VERSION ""

NS_ :

BS_:

BU_: IRTS_RR TLM ACQUISINATOR ACQUISINATOR IRTS_RR TLM IRTS_RR TLM ACQUISINATOR IRTS_RR TLM TLM ACQUISINATOR ACQUISINATOR TLM ACQUISINATOR TLM TLM ACQUISINATOR ACQUISINATOR ECU TLM TLM DITOCAN ACQUISINATOR TLM TLM TLM TLM TLM ACQUISINATOR ACQUISINATOR ACQUISINATOR TLM TLM TLM ACQUISINATOR ACQUISINATOR ACQUISINATOR TLM TLM TLM ACQUISINATOR ACQUISINATOR TLM TLM TLM ECU ACQUISINATOR ECU TLM TLM ACQUISINATOR ECU TLM TLM ACQUISINATOR ACQUISINATOR TLM TLM TLM ACQUISINATOR ACQUISINATOR TLM ACQUISINATOR ACQUISINATOR ACQUISINATOR ACQUISINATOR TLM TLM ACQUISINATOR ACQUISINATOR ACQUISINATOR ACQUISINATOR ACQUISINATOR ACQUISINATOR TLM TLM ACQUISINATOR TLM TLM ACQUISINATOR TLM TLM TLM TLM ACQUISINATOR ACQUISINATOR TLM TLM TLM ANY TLM ACQUISINATOR ANY TLM TLM ACQUISINATOR ANY ACQUISINATOR ANY ACQUISINATOR TLM TLM ACQUISINATOR TLM ACQUISINATOR ACQUISINATOR ACQUISINATOR ACQUISINATOR TLM TLM ACQUISINATOR TLM TLM ACQUISINATOR ACQUISINATOR ACQUISINATOR TLM TLM ACQUISINATOR ACQUISINATOR TLM ACQUISINATOR TLM TLM TLM ACQUISINATOR ACQUISINATOR TLM ACQUISINATOR TLM TLM ACQUISINATOR TLM TLM TLM ACQUISINATOR TLM TLM ACQUISINATOR ACQUISINATOR TLM ACQUISINATOR ACQUISINATOR ACQUISINATOR TLM ACQUISINATOR TLM ACQUISINATOR TLM ACQUISINATOR ACQUISINATOR TLM ACQUISINATOR TLM TLM ACQUISINATOR TLM ACQUISINATOR ACQUISINATOR IMU IMU IRTS_FL ACQUISINATOR IRTS_FL IRTS_FL IRTS_FL IRTS_FR TLM IRTS_FR ACQUISINATOR IRTS_FR TLM ACQUISINATOR ACQUISINATOR TLM TLM TLM ACQUISINATOR ACQUISINATOR TLM IRTS_FR ACQUISINATOR IRTS_RL ACQUISINATOR IRTS_RL IRTS_RL IRTS_RL

BO_ 0 ACQUISINATOR_JMP_TO_BLT: 1 Vector__XXX
 SG_ acquisinatore_id : 0|8@1+ (1,0) [0|255] "" Vector__XXX

BO_ 1 ACQUISINATOR_FLASH_0_TX: 0 Vector__XXX

BO_ 2 ACQUISINATOR_FLASH_0_RX: 0 Vector__XXX

BO_ 3 ACQUISINATOR_FLASH_1_TX: 0 Vector__XXX

BO_ 4 ACQUISINATOR_FLASH_1_RX: 0 Vector__XXX

BO_ 5 ACQUISINATOR_FLASH_2_TX: 0 Vector__XXX

BO_ 6 ACQUISINATOR_FLASH_2_RX: 0 Vector__XXX

BO_ 7 ACQUISINATOR_FLASH_3_TX: 0 Vector__XXX

BO_ 8 ACQUISINATOR_FLASH_3_RX: 0 Vector__XXX

BO_ 9 ACQUISINATOR_FLASH_4_TX: 0 Vector__XXX

BO_ 10 ACQUISINATOR_FLASH_4_RX: 0 Vector__XXX

BO_ 11 ACQUISINATOR_FLASH_5_TX: 0 Vector__XXX

BO_ 12 ACQUISINATOR_FLASH_5_RX: 0 Vector__XXX

BO_ 13 ACQUISINATOR_FLASH_6_TX: 0 Vector__XXX

BO_ 14 ACQUISINATOR_FLASH_6_RX: 0 Vector__XXX

BO_ 15 ACQUISINATOR_FLASH_7_TX: 0 Vector__XXX

BO_ 16 ACQUISINATOR_FLASH_7_RX: 0 Vector__XXX

BO_ 17 ACQUISINATOR_FLASH_8_TX: 0 Vector__XXX

BO_ 18 ACQUISINATOR_FLASH_8_RX: 0 Vector__XXX

BO_ 19 ACQUISINATOR_FLASH_9_TX: 0 Vector__XXX

BO_ 20 ACQUISINATOR_FLASH_9_RX: 0 Vector__XXX

BO_ 21 ACQUISINATOR_FLASH_10_TX: 0 Vector__XXX

BO_ 22 ACQUISINATOR_FLASH_10_RX: 0 Vector__XXX

BO_ 23 ACQUISINATOR_FLASH_11_TX: 0 Vector__XXX

BO_ 24 ACQUISINATOR_FLASH_11_RX: 0 Vector__XXX

BO_ 25 ACQUISINATOR_FLASH_12_TX: 0 Vector__XXX

BO_ 26 ACQUISINATOR_FLASH_12_RX: 0 Vector__XXX

BO_ 27 ACQUISINATOR_FLASH_13_TX: 0 Vector__XXX

BO_ 28 ACQUISINATOR_FLASH_13_RX: 0 Vector__XXX

BO_ 29 ACQUISINATOR_FLASH_14_TX: 0 Vector__XXX

BO_ 30 ACQUISINATOR_FLASH_14_RX: 0 Vector__XXX

BO_ 31 ACQUISINATOR_FLASH_15_TX: 0 Vector__XXX

BO_ 32 ACQUISINATOR_FLASH_15_RX: 0 Vector__XXX

BO_ 33 ACQUISINATOR_FLASH_16_TX: 0 Vector__XXX

BO_ 34 ACQUISINATOR_FLASH_16_RX: 0 Vector__XXX

BO_ 35 ACQUISINATOR_FLASH_17_TX: 0 Vector__XXX

BO_ 36 ACQUISINATOR_FLASH_17_RX: 0 Vector__XXX

BO_ 37 ACQUISINATOR_FLASH_18_TX: 0 Vector__XXX

BO_ 38 ACQUISINATOR_FLASH_18_RX: 0 Vector__XXX

BO_ 39 ACQUISINATOR_FLASH_19_TX: 0 Vector__XXX

BO_ 40 ACQUISINATOR_FLASH_19_RX: 0 Vector__XXX

BO_ 41 ACQUISINATOR_FLASH_20_TX: 0 Vector__XXX

BO_ 42 ACQUISINATOR_FLASH_20_RX: 0 Vector__XXX

BO_ 43 ACQUISINATOR_FLASH_21_TX: 0 Vector__XXX

BO_ 44 ACQUISINATOR_FLASH_21_RX: 0 Vector__XXX

BO_ 45 ACQUISINATOR_FLASH_22_TX: 0 Vector__XXX

BO_ 46 ACQUISINATOR_FLASH_22_RX: 0 Vector__XXX

BO_ 47 ACQUISINATOR_FLASH_23_TX: 0 Vector__XXX

BO_ 48 ACQUISINATOR_FLASH_23_RX: 0 Vector__XXX

BO_ 49 ACQUISINATOR_FLASH_24_TX: 0 Vector__XXX

BO_ 50 ACQUISINATOR_FLASH_24_RX: 0 Vector__XXX

BO_ 51 ACQUISINATOR_FLASH_25_TX: 0 Vector__XXX

BO_ 52 ACQUISINATOR_FLASH_25_RX: 0 Vector__XXX

BO_ 53 ACQUISINATOR_FLASH_26_TX: 0 Vector__XXX

BO_ 54 ACQUISINATOR_FLASH_26_RX: 0 Vector__XXX

BO_ 55 ACQUISINATOR_FLASH_27_TX: 0 Vector__XXX

BO_ 56 ACQUISINATOR_FLASH_27_RX: 0 Vector__XXX

BO_ 57 ACQUISINATOR_FLASH_28_TX: 0 Vector__XXX

BO_ 58 ACQUISINATOR_FLASH_28_RX: 0 Vector__XXX

BO_ 59 ACQUISINATOR_FLASH_29_TX: 0 Vector__XXX

BO_ 60 ACQUISINATOR_FLASH_29_RX: 0 Vector__XXX

BO_ 61 ACQUISINATOR_FLASH_30_TX: 0 Vector__XXX

BO_ 62 ACQUISINATOR_FLASH_30_RX: 0 Vector__XXX

BO_ 63 ACQUISINATOR_FLASH_31_TX: 0 Vector__XXX

BO_ 64 ACQUISINATOR_FLASH_31_RX: 0 Vector__XXX

BO_ 700 ACQUISINATOR_VERSION: 5 Vector__XXX
 SG_ canlib_build_time : 8|32@1+ (1,0) [0|4294967295] "" Vector__XXX
 SG_ acquisinator_id : 0|8@1+ (1,0) [0|255] "" Vector__XXX

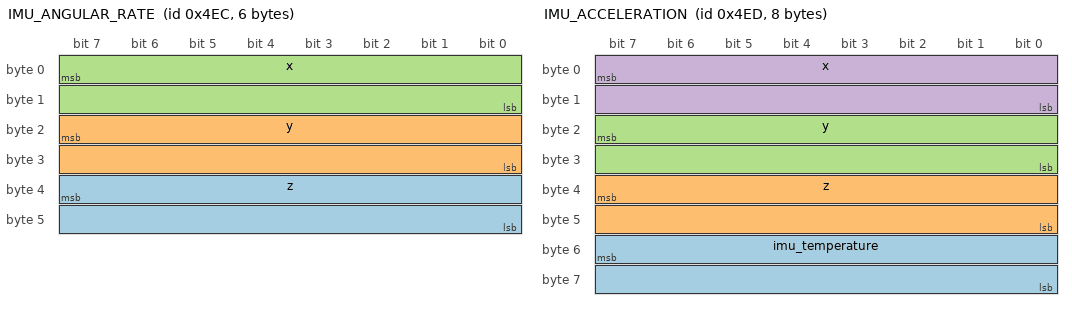
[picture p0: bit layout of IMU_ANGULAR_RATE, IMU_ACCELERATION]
BO_ 1260 IMU_ANGULAR_RATE: 6 Vector__XXX
 SG_ z : 39|16@0- (0.01,0) [0|245] "" Vector__XXX
 SG_ y : 23|16@0- (0.01,0) [0|245] "" Vector__XXX
 SG_ x : 7|16@0- (0.01,0) [0|245] "" Vector__XXX

BO_ 1261 IMU_ACCELERATION: 8 Vector__XXX
 SG_ imu_temperature : 55|16@0- (1,-32768) [-32768|32767] "" Vector__XXX
 SG_ z : 39|16@0- (0.01,0) [0|8] "" Vector__XXX
 SG_ y : 23|16@0- (0.01,0) [0|8] "" Vector__XXX
 SG_ x : 7|16@0- (0.01,0) [0|8] "" Vector__XXX

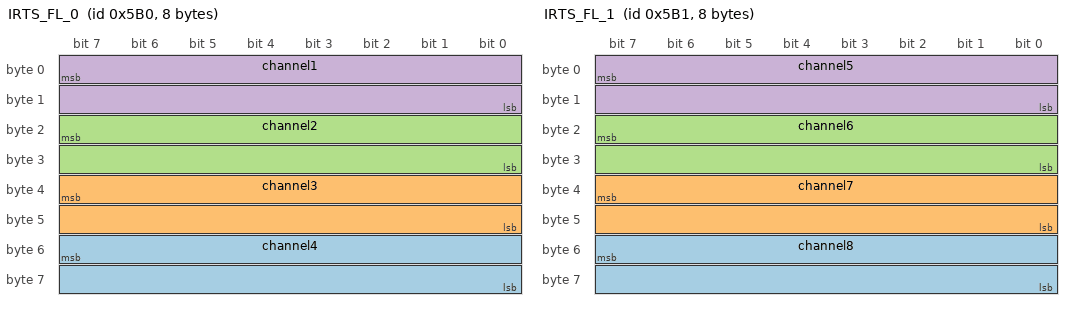
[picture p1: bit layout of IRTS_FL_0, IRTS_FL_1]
BO_ 1456 IRTS_FL_0: 8 Vector__XXX
 SG_ channel4 : 55|16@0+ (0.1,-100) [-100|0] "" Vector__XXX
 SG_ channel3 : 39|16@0+ (0.1,-100) [-100|0] "" Vector__XXX
 SG_ channel2 : 23|16@0+ (0.1,-100) [-100|0] "" Vector__XXX
 SG_ channel1 : 7|16@0+ (0.1,-100) [-100|0] "" Vector__XXX

BO_ 1457 IRTS_FL_1: 8 Vector__XXX
 SG_ channel8 : 55|16@0+ (0.1,-100) [-100|0] "" Vector__XXX
 SG_ channel7 : 39|16@0+ (0.1,-100) [-100|0] "" Vector__XXX
 SG_ channel6 : 23|16@0+ (0.1,-100) [-100|0] "" Vector__XXX
 SG_ channel5 : 7|16@0+ (0.1,-100) [-100|0] "" Vector__XXX

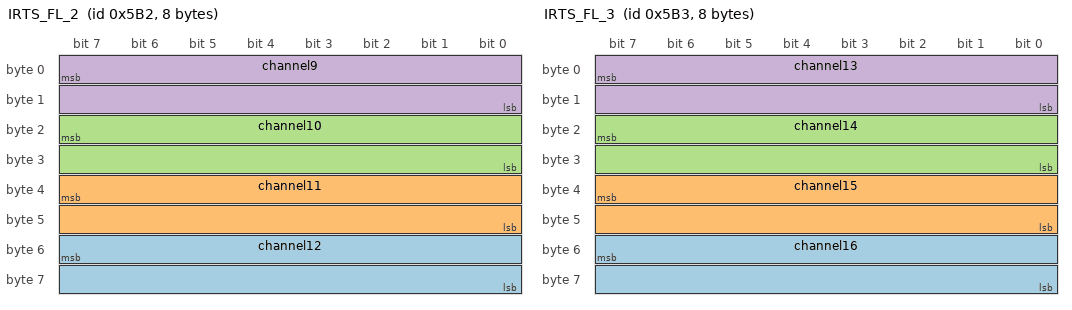
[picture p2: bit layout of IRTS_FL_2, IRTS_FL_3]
BO_ 1458 IRTS_FL_2: 8 Vector__XXX
 SG_ channel12 : 55|16@0+ (0.1,-100) [-100|0] "" Vector__XXX
 SG_ channel11 : 39|16@0+ (0.1,-100) [-100|0] "" Vector__XXX
 SG_ channel10 : 23|16@0+ (0.1,-100) [-100|0] "" Vector__XXX
 SG_ channel9 : 7|16@0+ (0.1,-100) [-100|0] "" Vector__XXX

BO_ 1459 IRTS_FL_3: 8 Vector__XXX
 SG_ channel16 : 55|16@0+ (0.1,-100) [-100|0] "" Vector__XXX
 SG_ channel15 : 39|16@0+ (0.1,-100) [-100|0] "" Vector__XXX
 SG_ channel14 : 23|16@0+ (0.1,-100) [-100|0] "" Vector__XXX
 SG_ channel13 : 7|16@0+ (0.1,-100) [-100|0] "" Vector__XXX

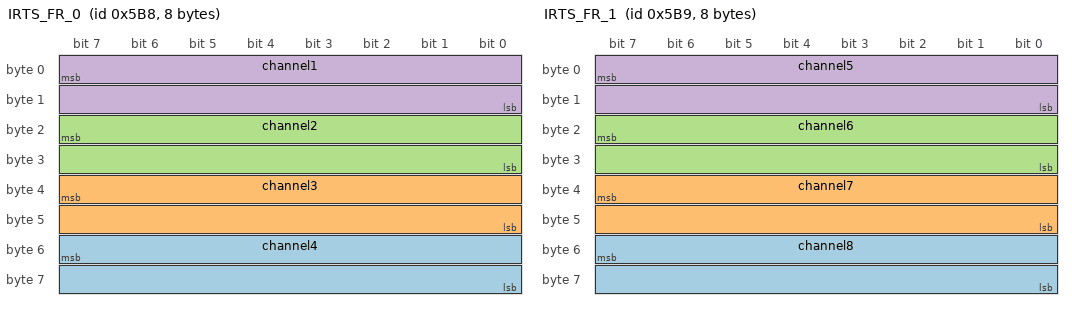
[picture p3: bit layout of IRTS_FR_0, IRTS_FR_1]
BO_ 1464 IRTS_FR_0: 8 Vector__XXX
 SG_ channel4 : 55|16@0+ (0.1,-100) [-100|0] "" Vector__XXX
 SG_ channel3 : 39|16@0+ (0.1,-100) [-100|0] "" Vector__XXX
 SG_ channel2 : 23|16@0+ (0.1,-100) [-100|0] "" Vector__XXX
 SG_ channel1 : 7|16@0+ (0.1,-100) [-100|0] "" Vector__XXX

BO_ 1465 IRTS_FR_1: 8 Vector__XXX
 SG_ channel8 : 55|16@0+ (0.1,-100) [-100|0] "" Vector__XXX
 SG_ channel7 : 39|16@0+ (0.1,-100) [-100|0] "" Vector__XXX
 SG_ channel6 : 23|16@0+ (0.1,-100) [-100|0] "" Vector__XXX
 SG_ channel5 : 7|16@0+ (0.1,-100) [-100|0] "" Vector__XXX

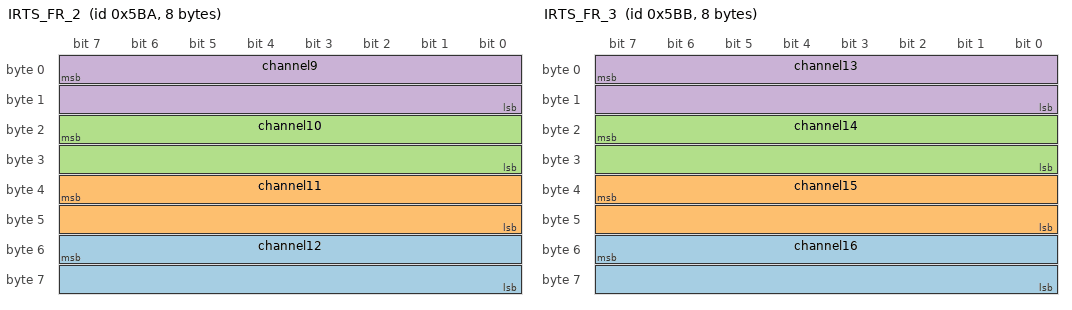
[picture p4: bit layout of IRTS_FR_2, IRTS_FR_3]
BO_ 1466 IRTS_FR_2: 8 Vector__XXX
 SG_ channel12 : 55|16@0+ (0.1,-100) [-100|0] "" Vector__XXX
 SG_ channel11 : 39|16@0+ (0.1,-100) [-100|0] "" Vector__XXX
 SG_ channel10 : 23|16@0+ (0.1,-100) [-100|0] "" Vector__XXX
 SG_ channel9 : 7|16@0+ (0.1,-100) [-100|0] "" Vector__XXX

BO_ 1467 IRTS_FR_3: 8 Vector__XXX
 SG_ channel16 : 55|16@0+ (0.1,-100) [-100|0] "" Vector__XXX
 SG_ channel15 : 39|16@0+ (0.1,-100) [-100|0] "" Vector__XXX
 SG_ channel14 : 23|16@0+ (0.1,-100) [-100|0] "" Vector__XXX
 SG_ channel13 : 7|16@0+ (0.1,-100) [-100|0] "" Vector__XXX

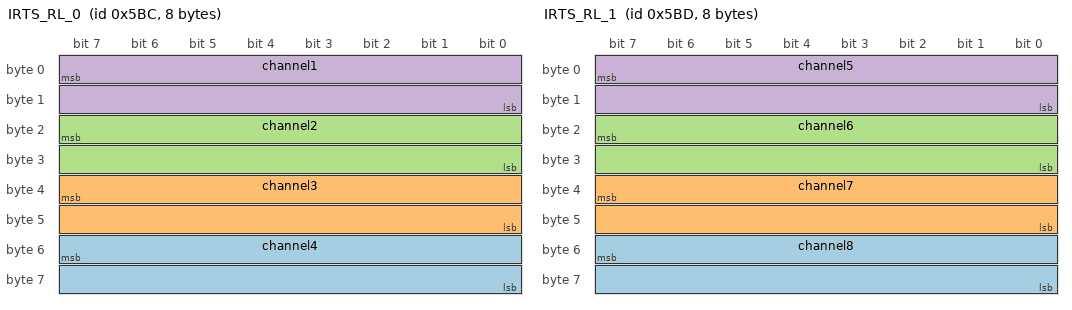
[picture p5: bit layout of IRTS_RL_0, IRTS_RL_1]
BO_ 1468 IRTS_RL_0: 8 Vector__XXX
 SG_ channel4 : 55|16@0+ (0.1,-100) [-100|0] "" Vector__XXX
 SG_ channel3 : 39|16@0+ (0.1,-100) [-100|0] "" Vector__XXX
 SG_ channel2 : 23|16@0+ (0.1,-100) [-100|0] "" Vector__XXX
 SG_ channel1 : 7|16@0+ (0.1,-100) [-100|0] "" Vector__XXX

BO_ 1469 IRTS_RL_1: 8 Vector__XXX
 SG_ channel8 : 55|16@0+ (0.1,-100) [-100|0] "" Vector__XXX
 SG_ channel7 : 39|16@0+ (0.1,-100) [-100|0] "" Vector__XXX
 SG_ channel6 : 23|16@0+ (0.1,-100) [-100|0] "" Vector__XXX
 SG_ channel5 : 7|16@0+ (0.1,-100) [-100|0] "" Vector__XXX

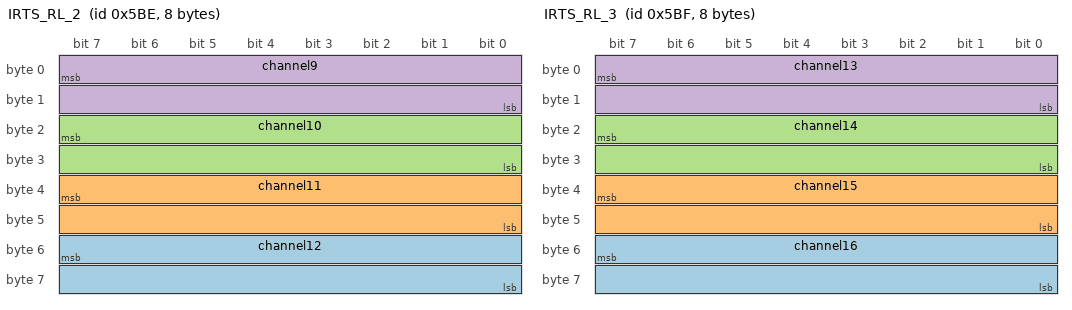
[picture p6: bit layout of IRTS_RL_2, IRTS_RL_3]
BO_ 1470 IRTS_RL_2: 8 Vector__XXX
 SG_ channel12 : 55|16@0+ (0.1,-100) [-100|0] "" Vector__XXX
 SG_ channel11 : 39|16@0+ (0.1,-100) [-100|0] "" Vector__XXX
 SG_ channel10 : 23|16@0+ (0.1,-100) [-100|0] "" Vector__XXX
 SG_ channel9 : 7|16@0+ (0.1,-100) [-100|0] "" Vector__XXX

BO_ 1471 IRTS_RL_3: 8 Vector__XXX
 SG_ channel16 : 55|16@0+ (0.1,-100) [-100|0] "" Vector__XXX
 SG_ channel15 : 39|16@0+ (0.1,-100) [-100|0] "" Vector__XXX
 SG_ channel14 : 23|16@0+ (0.1,-100) [-100|0] "" Vector__XXX
 SG_ channel13 : 7|16@0+ (0.1,-100) [-100|0] "" Vector__XXX

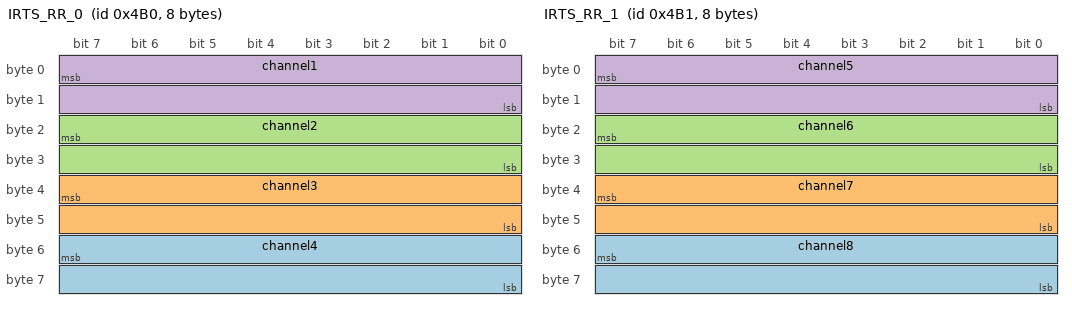
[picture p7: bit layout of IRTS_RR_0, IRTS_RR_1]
BO_ 1200 IRTS_RR_0: 8 Vector__XXX
 SG_ channel4 : 55|16@0+ (0.1,-100) [-100|0] "" Vector__XXX
 SG_ channel3 : 39|16@0+ (0.1,-100) [-100|0] "" Vector__XXX
 SG_ channel2 : 23|16@0+ (0.1,-100) [-100|0] "" Vector__XXX
 SG_ channel1 : 7|16@0+ (0.1,-100) [-100|0] "" Vector__XXX

BO_ 1201 IRTS_RR_1: 8 Vector__XXX
 SG_ channel8 : 55|16@0+ (0.1,-100) [-100|0] "" Vector__XXX
 SG_ channel7 : 39|16@0+ (0.1,-100) [-100|0] "" Vector__XXX
 SG_ channel6 : 23|16@0+ (0.1,-100) [-100|0] "" Vector__XXX
 SG_ channel5 : 7|16@0+ (0.1,-100) [-100|0] "" Vector__XXX

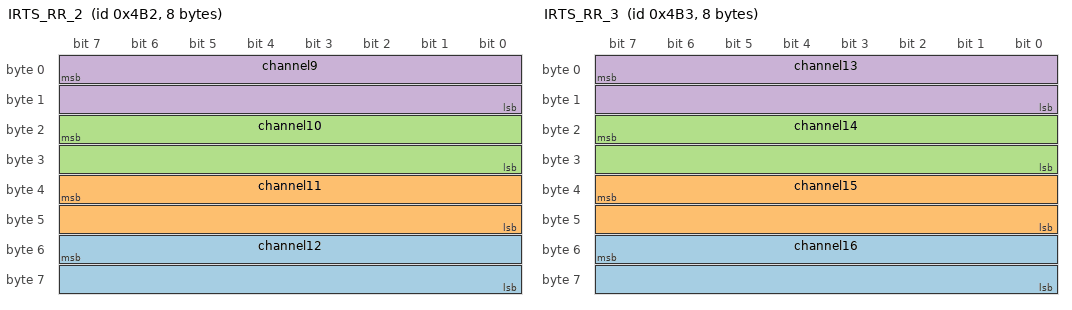
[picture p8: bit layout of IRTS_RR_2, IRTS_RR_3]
BO_ 1202 IRTS_RR_2: 8 Vector__XXX
 SG_ channel12 : 55|16@0+ (0.1,-100) [-100|0] "" Vector__XXX
 SG_ channel11 : 39|16@0+ (0.1,-100) [-100|0] "" Vector__XXX
 SG_ channel10 : 23|16@0+ (0.1,-100) [-100|0] "" Vector__XXX
 SG_ channel9 : 7|16@0+ (0.1,-100) [-100|0] "" Vector__XXX

BO_ 1203 IRTS_RR_3: 8 Vector__XXX
 SG_ channel16 : 55|16@0+ (0.1,-100) [-100|0] "" Vector__XXX
 SG_ channel15 : 39|16@0+ (0.1,-100) [-100|0] "" Vector__XXX
 SG_ channel14 : 23|16@0+ (0.1,-100) [-100|0] "" Vector__XXX
 SG_ channel13 : 7|16@0+ (0.1,-100) [-100|0] "" Vector__XXX

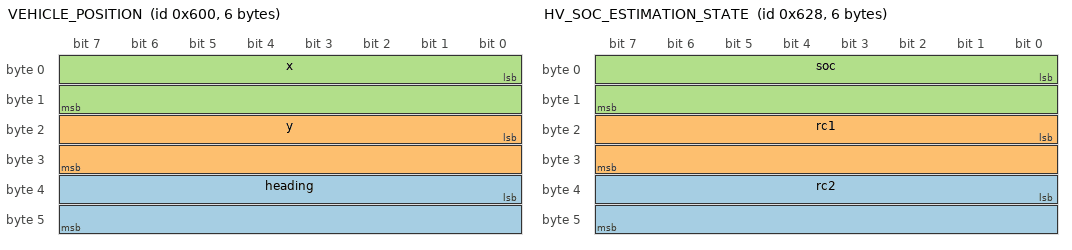
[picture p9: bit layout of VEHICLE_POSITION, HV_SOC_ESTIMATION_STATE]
BO_ 1536 VEHICLE_POSITION: 6 Vector__XXX
 SG_ heading : 32|16@1+ (9.587518120088503e-05,-3.14159) [-3.14159|3.14159] "" Vector__XXX
 SG_ y : 16|16@1+ (0.030518043793392843,-1000) [-1000|1000] "" Vector__XXX
 SG_ x : 0|16@1+ (0.030518043793392843,-1000) [-1000|1000] "" Vector__XXX

BO_ 1544 VEHICLE_SPEED: 4 Vector__XXX
 SG_ v : 16|16@1+ (0.0006103608758678569,-20) [-20|20] "" Vector__XXX
 SG_ u : 0|16@1+ (0.0006103608758678569,0) [0|40] "" Vector__XXX

BO_ 1552 VEHICLE_CURVILINEAR_COORDINATES: 6 Vector__XXX
 SG_ n : 32|16@1+ (0.00030518043793392844,-10) [-10|10] "" Vector__XXX
 SG_ s : 0|32@1+ (1.1641532185403987e-06,0) [0|5000] "" Vector__XXX

BO_ 1560 FRONT_ANGULAR_VELOCITY: 4 Vector__XXX
 SG_ fr : 16|16@1+ (0.006103608758678569,-200) [-200|200] "" Vector__XXX
 SG_ fl : 0|16@1+ (0.006103608758678569,-200) [-200|200] "" Vector__XXX

BO_ 1568 REAR_ANGULAR_VELOCITY: 4 Vector__XXX
 SG_ rr : 16|16@1+ (0.006103608758678569,-200) [-200|200] "" Vector__XXX
 SG_ rl : 0|16@1+ (0.006103608758678569,-200) [-200|200] "" Vector__XXX

BO_ 1576 HV_SOC_ESTIMATION_STATE: 6 Vector__XXX
 SG_ rc2 : 32|16@1+ (6.86655985351339e-05,0) [0|4.5] "" Vector__XXX
 SG_ rc1 : 16|16@1+ (6.86655985351339e-05,0) [0|4.5] "" Vector__XXX
 SG_ soc : 0|16@1+ (1.5259021896696422e-05,0) [0|1] "" Vector__XXX

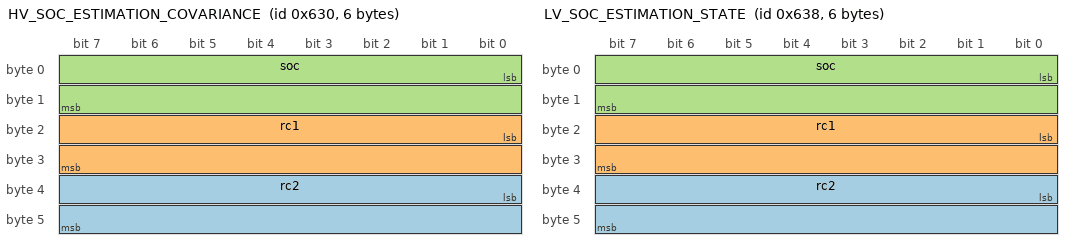
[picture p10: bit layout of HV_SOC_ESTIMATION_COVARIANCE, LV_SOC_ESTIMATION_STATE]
BO_ 1584 HV_SOC_ESTIMATION_COVARIANCE: 6 Vector__XXX
 SG_ rc2 : 32|16@1+ (0.0015259021896696422,0) [0|100] "" Vector__XXX
 SG_ rc1 : 16|16@1+ (0.0015259021896696422,0) [0|100] "" Vector__XXX
 SG_ soc : 0|16@1+ (0.00015259021896696422,0) [0|10] "" Vector__XXX

BO_ 1592 LV_SOC_ESTIMATION_STATE: 6 Vector__XXX
 SG_ rc2 : 32|16@1+ (6.86655985351339e-05,0) [0|4.5] "" Vector__XXX
 SG_ rc1 : 16|16@1+ (6.86655985351339e-05,0) [0|4.5] "" Vector__XXX
 SG_ soc : 0|16@1+ (1.5259021896696422e-05,0) [0|1] "" Vector__XXX

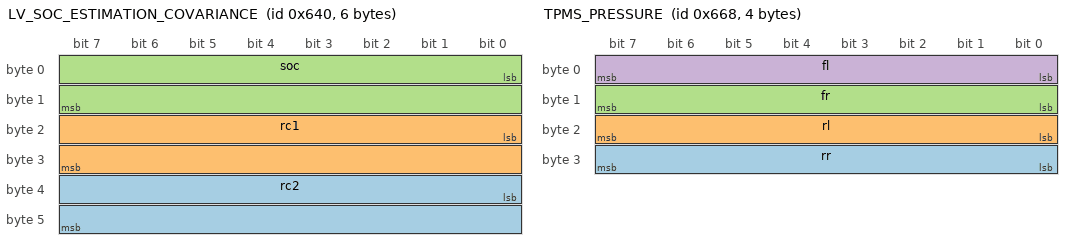
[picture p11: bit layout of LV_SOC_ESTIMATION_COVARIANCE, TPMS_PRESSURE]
BO_ 1600 LV_SOC_ESTIMATION_COVARIANCE: 6 Vector__XXX
 SG_ rc2 : 32|16@1+ (0.0015259021896696422,0) [0|100] "" Vector__XXX
 SG_ rc1 : 16|16@1+ (0.0015259021896696422,0) [0|100] "" Vector__XXX
 SG_ soc : 0|16@1+ (0.00015259021896696422,0) [0|10] "" Vector__XXX

BO_ 1608 PEDAL_THROTTLE: 2 Vector__XXX
 SG_ throttle : 0|16@1+ (1.5259021896696422e-05,0) [0|1] "" Vector__XXX

BO_ 1616 PEDAL_BRAKES_PRESSURE: 4 Vector__XXX
 SG_ rear : 16|16@1+ (0.0015259021896696422,0) [0|100] "" Vector__XXX
 SG_ front : 0|16@1+ (0.0015259021896696422,0) [0|100] "" Vector__XXX

BO_ 1624 STEER_ANGLE: 4 Vector__XXX
 SG_ angle : 0|32@1+ (8.38190317349087e-08,-180) [-180|180] "" Vector__XXX

BO_ 1632 ODOMETER: 4 Vector__XXX
 SG_ kilometers : 0|32@1+ (0.00023283064370807974,0) [0|1000000] "" Vector__XXX

BO_ 1640 TPMS_PRESSURE: 4 Vector__XXX
 SG_ rr : 24|8@1+ (1.0,0) [0|255] "" Vector__XXX
 SG_ rl : 16|8@1+ (1.0,0) [0|255] "" Vector__XXX
 SG_ fr : 8|8@1+ (1.0,0) [0|255] "" Vector__XXX
 SG_ fl : 0|8@1+ (1.0,0) [0|255] "" Vector__XXX

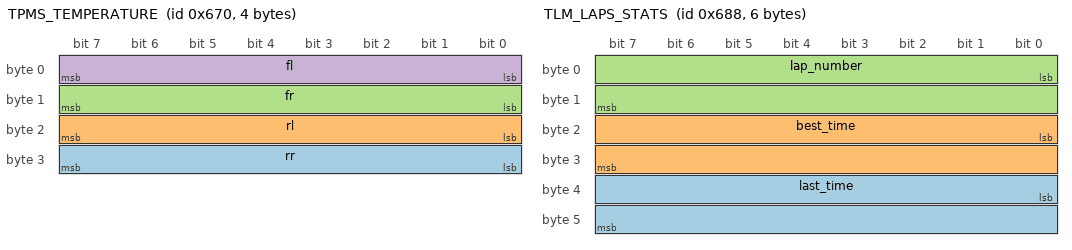
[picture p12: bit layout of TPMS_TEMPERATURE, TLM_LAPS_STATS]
BO_ 1648 TPMS_TEMPERATURE: 4 Vector__XXX
 SG_ rr : 24|8@1+ (1.0,0) [0|255] "" Vector__XXX
 SG_ rl : 16|8@1+ (1.0,0) [0|255] "" Vector__XXX
 SG_ fr : 8|8@1+ (1.0,0) [0|255] "" Vector__XXX
 SG_ fl : 0|8@1+ (1.0,0) [0|255] "" Vector__XXX

BO_ 1656 TLM_UNIX_TIMESTAMP: 8 Vector__XXX
 SG_ timestamp : 0|64@1+ (1,0) [0|18446744073709551615] "" Vector__XXX

BO_ 1664 TLM_LAP_TIME: 4 Vector__XXX
 SG_ lap_time : 16|16@1+ (0.015259021896696421,0) [0|1000] "" Vector__XXX
 SG_ lap_count : 0|16@1+ (1,0) [0|65535] "" Vector__XXX

BO_ 1672 TLM_LAPS_STATS: 6 Vector__XXX
 SG_ last_time : 32|16@1+ (0.015259021896696421,0) [0|1000] "" Vector__XXX
 SG_ best_time : 16|16@1+ (0.015259021896696421,0) [0|1000] "" Vector__XXX
 SG_ lap_number : 0|16@1+ (1,0) [0|65535] "" Vector__XXX

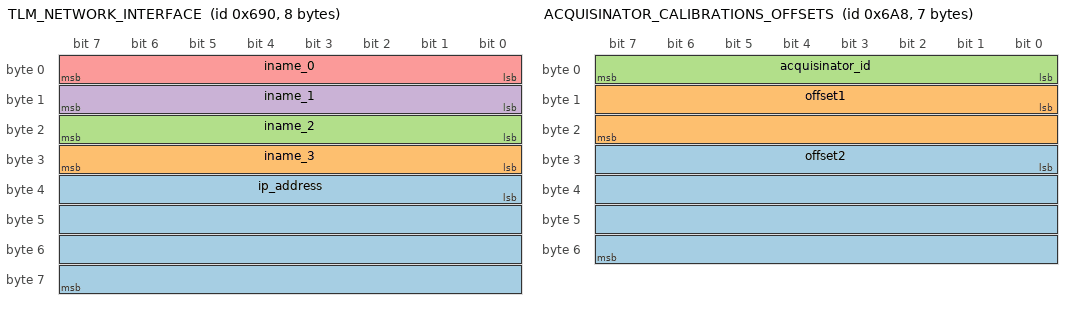
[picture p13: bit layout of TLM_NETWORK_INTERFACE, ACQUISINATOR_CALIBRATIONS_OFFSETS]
BO_ 1680 TLM_NETWORK_INTERFACE: 8 Vector__XXX
 SG_ ip_address : 32|32@1+ (1,0) [0|4294967295] "" Vector__XXX
 SG_ iname_3 : 24|8@1+ (1,0) [0|255] "" Vector__XXX
 SG_ iname_2 : 16|8@1+ (1,0) [0|255] "" Vector__XXX
 SG_ iname_1 : 8|8@1+ (1,0) [0|255] "" Vector__XXX
 SG_ iname_0 : 0|8@1+ (1,0) [0|255] "" Vector__XXX

BO_ 1688 FRONT_AMMO_COMPRESSION: 4 Vector__XXX
 SG_ fr : 16|16@1+ (0.0030518043793392844,-100) [-100|100] "" Vector__XXX
 SG_ fl : 0|16@1+ (0.0030518043793392844,-100) [-100|100] "" Vector__XXX

BO_ 1696 REAR_AMMO_COMPRESSION: 4 Vector__XXX
 SG_ rr : 16|16@1+ (0.0030518043793392844,-100) [-100|100] "" Vector__XXX
 SG_ rl : 0|16@1+ (0.0030518043793392844,-100) [-100|100] "" Vector__XXX

BO_ 1704 ACQUISINATOR_CALIBRATIONS_OFFSETS: 7 Vector__XXX
 SG_ offset2 : 24|32@1+ (4.656612874161595e-08,-100.0) [-100.0|100.0] "" Vector__XXX
 SG_ offset1 : 8|16@1+ (0.0030518043793392844,-100.0) [-100.0|100.0] "" Vector__XXX
 SG_ acquisinator_id : 0|8@1+ (1,0) [0|255] "" Vector__XXX

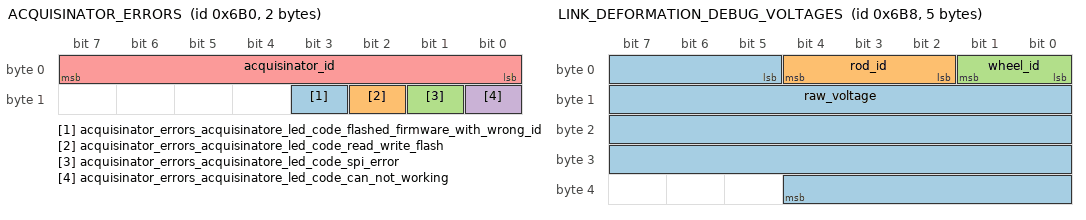
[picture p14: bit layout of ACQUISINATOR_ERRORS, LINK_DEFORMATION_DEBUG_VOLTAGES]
BO_ 1712 ACQUISINATOR_ERRORS: 2 Vector__XXX
 SG_ acquisinator_errors_acquisinatore_led_code_flashed_firmware_with_wrong_id : 11|1@1+ (1,0) [0|1] "" Vector__XXX
 SG_ acquisinator_errors_acquisinatore_led_code_read_write_flash : 10|1@1+ (1,0) [0|1] "" Vector__XXX
 SG_ acquisinator_errors_acquisinatore_led_code_spi_error : 9|1@1+ (1,0) [0|1] "" Vector__XXX
 SG_ acquisinator_errors_acquisinatore_led_code_can_not_working : 8|1@1+ (1,0) [0|1] "" Vector__XXX
 SG_ acquisinator_id : 0|8@1+ (1,0) [0|255] "" Vector__XXX

BO_ 1720 LINK_DEFORMATION_DEBUG_VOLTAGES: 5 Vector__XXX
 SG_ raw_voltage : 5|32@1+ (8.149072529782791e-10,0.0) [0.0|3.5] "" Vector__XXX
 SG_ rod_id : 2|3@1+ (1,0) [0|7] "" Vector__XXX
 SG_ wheel_id : 0|2@1+ (1,0) [0|3] "" Vector__XXX

BO_ 1728 LINK_DEFORMATION_FL_WHEEL: 5 Vector__XXX
 SG_ deformation : 3|32@1+ (4.656612874161595e-12,-0.01) [-0.01|0.01] "" Vector__XXX
 SG_ rod_id : 0|3@1+ (1,0) [0|7] "" Vector__XXX

BO_ 1736 LINK_DEFORMATION_FR_WHEEL: 5 Vector__XXX
 SG_ deformation : 3|32@1+ (4.656612874161595e-12,-0.01) [-0.01|0.01] "" Vector__XXX
 SG_ rod_id : 0|3@1+ (1,0) [0|7] "" Vector__XXX

BO_ 1744 LINK_DEFORMATION_RL_WHEEL: 5 Vector__XXX
 SG_ deformation : 3|32@1+ (4.656612874161595e-12,-0.01) [-0.01|0.01] "" Vector__XXX
 SG_ rod_id : 0|3@1+ (1,0) [0|7] "" Vector__XXX

BO_ 1752 LINK_DEFORMATION_RR_WHEEL: 5 Vector__XXX
 SG_ deformation : 3|32@1+ (4.656612874161595e-12,-0.01) [-0.01|0.01] "" Vector__XXX
 SG_ rod_id : 0|3@1+ (1,0) [0|7] "" Vector__XXX

BO_ 72 LINK_DEFORMATION_SET_CALIBRATION: 0 Vector__XXX

BO_ 80 AMMO_COMPRESSION_SET_CALIBRATION: 0 Vector__XXX

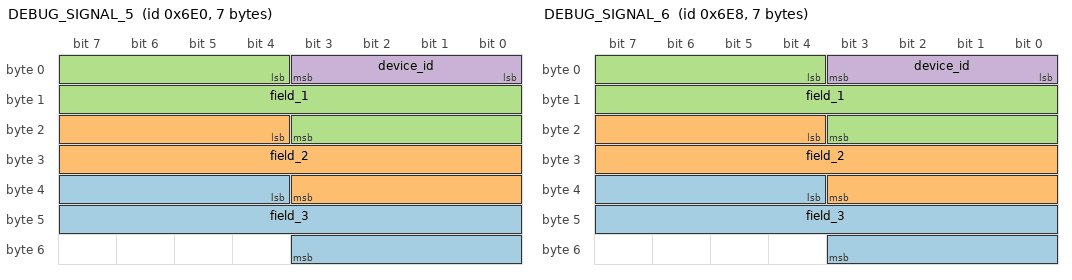
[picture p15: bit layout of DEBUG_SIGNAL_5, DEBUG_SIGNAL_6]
BO_ 1760 DEBUG_SIGNAL_5: 7 Vector__XXX
 SG_ field_3 : 36|16@1+ (3.0518043793392844e-05,-1) [-1|1] "" Vector__XXX
 SG_ field_2 : 20|16@1+ (3.0518043793392844e-05,-1) [-1|1] "" Vector__XXX
 SG_ field_1 : 4|16@1+ (3.0518043793392844e-05,-1) [-1|1] "" Vector__XXX
 SG_ device_id : 0|4@1+ (1,0) [0|15] "" Vector__XXX

BO_ 1768 DEBUG_SIGNAL_6: 7 Vector__XXX
 SG_ field_3 : 36|16@1+ (3.0518043793392844e-05,-1) [-1|1] "" Vector__XXX
 SG_ field_2 : 20|16@1+ (3.0518043793392844e-05,-1) [-1|1] "" Vector__XXX
 SG_ field_1 : 4|16@1+ (3.0518043793392844e-05,-1) [-1|1] "" Vector__XXX
 SG_ device_id : 0|4@1+ (1,0) [0|15] "" Vector__XXX

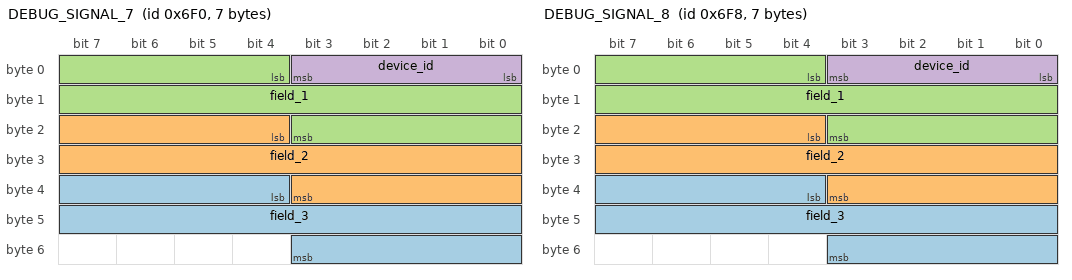
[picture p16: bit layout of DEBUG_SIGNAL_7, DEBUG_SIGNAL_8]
BO_ 1776 DEBUG_SIGNAL_7: 7 Vector__XXX
 SG_ field_3 : 36|16@1+ (3.0518043793392844e-05,-1) [-1|1] "" Vector__XXX
 SG_ field_2 : 20|16@1+ (3.0518043793392844e-05,-1) [-1|1] "" Vector__XXX
 SG_ field_1 : 4|16@1+ (3.0518043793392844e-05,-1) [-1|1] "" Vector__XXX
 SG_ device_id : 0|4@1+ (1,0) [0|15] "" Vector__XXX

BO_ 1784 DEBUG_SIGNAL_8: 7 Vector__XXX
 SG_ field_3 : 36|16@1+ (3.0518043793392844e-05,-1) [-1|1] "" Vector__XXX
 SG_ field_2 : 20|16@1+ (3.0518043793392844e-05,-1) [-1|1] "" Vector__XXX
 SG_ field_1 : 4|16@1+ (3.0518043793392844e-05,-1) [-1|1] "" Vector__XXX
 SG_ device_id : 0|4@1+ (1,0) [0|15] "" Vector__XXX

BO_ 1792 COOLING_TEMP_PUMPS: 4 Vector__XXX
 SG_ output : 16|16@1+ (0.0018310826276035706,-10) [-10|110] "" Vector__XXX
 SG_ input : 0|16@1+ (0.0018310826276035706,-10) [-10|110] "" Vector__XXX

BO_ 1800 COOLING_TEMP_RADIATORS: 2 Vector__XXX
 SG_ air_temp : 0|16@1+ (0.0018310826276035706,-10) [-10|110] "" Vector__XXX

BO_ 1808 LATERAL_CONTROLLER_PREVIEW_POINT_ERRORS: 4 Vector__XXX
 SG_ distance : 16|16@1+ (0.00030518043793392844,-10) [-10|10] "" Vector__XXX
 SG_ heading : 0|16@1+ (9.587518120088503e-05,-3.14159) [-3.14159|3.14159] "" Vector__XXX

BO_ 1816 LATERAL_CONTROLLER_ERRORS: 2 Vector__XXX
 SG_ com_distance : 0|16@1+ (0.00030518043793392844,-10) [-10|10] "" Vector__XXX

CM_ BO_ 1260 "Inertial Measurement Unit [x,y,z]-axis angular rate value. 0.01dps per bit, Big-Endian, 16bit Total, signed";
CM_ BO_ 1261 "Inertial Measurement Unit [x,y,z]-axis acceleration value. 0.01g per bit, Big-Endian, 16bit Total, signed";
CM_ BO_ 1456 "Front Left wheel InfraRed Temperature Sensor data, channels 1 through 4. 0.1˚C per bit, -100˚C offset, Big-Endian, 16bit Total, unsigned.";
CM_ BO_ 1457 "Front Left wheel InfraRed Temperature Sensor data, channels 5 through 8. 0.1˚C per bit, -100˚C offset, Big-Endian, 16bit Total, unsigned.";
CM_ BO_ 1458 "Front Left wheel InfraRed Temperature Sensor data, channels 9 through 12. 0.1˚C per bit, -100˚C offset, Big-Endian, 16bit Total, unsigned.";
CM_ BO_ 1459 "Front Left wheel InfraRed Temperature Sensor data, channels 13 through 16. 0.1˚C per bit, -100˚C offset, Big-Endian, 16bit Total, unsigned.";
CM_ BO_ 1464 "Front Right wheel InfraRed Temperature Sensor data, channels 1 through 4. 0.1˚C per bit, -100˚C offset, Big-Endian, 16bit Total, unsigned.";
CM_ BO_ 1465 "Front Right wheel InfraRed Temperature Sensor data, channels 5 through 8. 0.1˚C per bit, -100˚C offset, Big-Endian, 16bit Total, unsigned.";
CM_ BO_ 1466 "Front Right wheel InfraRed Temperature Sensor data, channels 9 through 12. 0.1˚C per bit, -100˚C offset, Big-Endian, 16bit Total, unsigned.";
CM_ BO_ 1467 "Front Right wheel InfraRed Temperature Sensor data, channels 13 through 16. 0.1˚C per bit, -100˚C offset, Big-Endian, 16bit Total, unsigned.";
CM_ BO_ 1468 "Rear Left wheel InfraRed Temperature Sensor data, channels 1 through 4. 0.1˚C per bit, -100˚C offset, Big-Endian, 16bit Total, unsigned.";
CM_ BO_ 1469 "Rear Left wheel InfraRed Temperature Sensor data, channels 5 through 8. 0.1˚C per bit, -100˚C offset, Big-Endian, 16bit Total, unsigned.";
CM_ BO_ 1470 "Rear Left wheel InfraRed Temperature Sensor data, channels 9 through 12. 0.1˚C per bit, -100˚C offset, Big-Endian, 16bit Total, unsigned.";
CM_ BO_ 1471 "Rear Left wheel InfraRed Temperature Sensor data, channels 13 through 16. 0.1˚C per bit, -100˚C offset, Big-Endian, 16bit Total, unsigned.";
CM_ BO_ 1200 "Rear Right wheel InfraRed Temperature Sensor data, channels 1 through 4. 0.1˚C per bit, -100˚C offset, Big-Endian, 16bit Total, unsigned.";
CM_ BO_ 1201 "Rear Right wheel InfraRed Temperature Sensor data, channels 5 through 8. 0.1˚C per bit, -100˚C offset, Big-Endian, 16bit Total, unsigned.";
CM_ BO_ 1202 "Rear Right wheel InfraRed Temperature Sensor data, channels 9 through 12. 0.1˚C per bit, -100˚C offset, Big-Endian, 16bit Total, unsigned.";
CM_ BO_ 1203 "Rear Right wheel InfraRed Temperature Sensor data, channels 13 through 16. 0.1˚C per bit, -100˚C offset, Big-Endian, 16bit Total, unsigned.";
CM_ BO_ 1536 "Vehicle position in meters and heading in radians";
CM_ BO_ 1544 "Vehicle speed in m/s";
CM_ BO_ 1552 "Vehicle curvilinear coordinates wrt baseline";
CM_ BO_ 1560 "Front encoder speed in rad/sec";
CM_ BO_ 1568 "Rear encoders speed in rad/sec";
CM_ BO_ 1576 "State of Charge estimation state";
CM_ BO_ 1584 "State of Charge estimation covariance of the state";
CM_ BO_ 1592 "State of Charge estimation state";
CM_ BO_ 1600 "State of Charge estimation covariance of the state";
CM_ BO_ 1608 "Pedal Throttle , already calibrated";
CM_ BO_ 1616 "Pedal brakes pressures in bar, already calibrated";
CM_ BO_ 1624 "Steering angle in degrees";
CM_ BO_ 1632 "Cumulative kilometers count";
CM_ BO_ 1640 "Tire Pressure Monitoring System, pressure of each tire";
CM_ BO_ 1648 "Tire Pressure Monitoring System, temperature of each tire";
CM_ BO_ 1680 "Network interface from telemetry device, only IPV4";
CM_ BO_ 1688 "Front ammo compressions";
CM_ BO_ 1696 "Rear ammo compressions";
CM_ BO_ 1704 "Calibration offsets for acquisinators";
CM_ BO_ 1712 "Acquisinator errors";
CM_ BO_ 1720 "Debug message with raw voltages from strain gauges";
CM_ BO_ 1728 "Message for the arm deformation for the front left wheel";
CM_ BO_ 1736 "Message for the arm deformation for the front right wheel";
CM_ BO_ 1744 "Message for the arm deformation for the rear left wheel";
CM_ BO_ 1752 "Message for the arm deformation for the rear right wheel";
CM_ BO_ 72 "Calibration command for link deformation";
CM_ BO_ 80 "Calibration command for ammo compression";
CM_ BO_ 1760 "Debug signals";
CM_ BO_ 1768 "Debug signals";
CM_ BO_ 1776 "Debug signals";
CM_ BO_ 1784 "Debug signals";
CM_ BO_ 1792 "Temperature of pumps input to the radiator and output";
CM_ BO_ 1800 "Air temperature outside the radiator";
CM_ BO_ 1808 "Lateral controller (preview point) controller errors";
CM_ BO_ 1816 "Lateral controller errors";
BA_DEF_ BO_  "GenMsgCycleTime" INT 0 65535;
BA_DEF_DEF_  "GenMsgCycleTime" 0;
BA_ "GenMsgCycleTime" BO_ 700 1000;
BA_ "GenMsgCycleTime" BO_ 1536 10;
BA_ "GenMsgCycleTime" BO_ 1544 10;
BA_ "GenMsgCycleTime" BO_ 1552 10;
BA_ "GenMsgCycleTime" BO_ 1560 10;
BA_ "GenMsgCycleTime" BO_ 1568 10;
BA_ "GenMsgCycleTime" BO_ 1576 50;
BA_ "GenMsgCycleTime" BO_ 1584 50;
BA_ "GenMsgCycleTime" BO_ 1592 50;
BA_ "GenMsgCycleTime" BO_ 1600 50;
BA_ "GenMsgCycleTime" BO_ 1608 10;
BA_ "GenMsgCycleTime" BO_ 1616 10;
BA_ "GenMsgCycleTime" BO_ 1624 10;
BA_ "GenMsgCycleTime" BO_ 1632 1000;
BA_ "GenMsgCycleTime" BO_ 1656 1000;
BA_ "GenMsgCycleTime" BO_ 1672 1000;
BA_ "GenMsgCycleTime" BO_ 1680 1000;
BA_ "GenMsgCycleTime" BO_ 1688 10;
BA_ "GenMsgCycleTime" BO_ 1696 10;
BA_ "GenMsgCycleTime" BO_ 1704 1000;
BA_ "GenMsgCycleTime" BO_ 1712 1000;
BA_ "GenMsgCycleTime" BO_ 1720 10;
BA_ "GenMsgCycleTime" BO_ 1728 10;
BA_ "GenMsgCycleTime" BO_ 1736 10;
BA_ "GenMsgCycleTime" BO_ 1744 10;
BA_ "GenMsgCycleTime" BO_ 1752 10;
BA_ "GenMsgCycleTime" BO_ 1760 10;
BA_ "GenMsgCycleTime" BO_ 1768 10;
BA_ "GenMsgCycleTime" BO_ 1776 10;
BA_ "GenMsgCycleTime" BO_ 1784 10;
BA_ "GenMsgCycleTime" BO_ 1792 500;
BA_ "GenMsgCycleTime" BO_ 1800 500;
BA_ "GenMsgCycleTime" BO_ 1808 50;
BA_ "GenMsgCycleTime" BO_ 1816 50;
VAL_ 1720 rod_id 0 "F1011" 1 "F36" 2 "F46" 3 "F27" 4 "F17" 5 "F58" ;
VAL_ 1720 wheel_id 0 "fl" 1 "fr" 2 "rl" 3 "rr" ;
VAL_ 1728 rod_id 0 "F1011" 1 "F36" 2 "F46" 3 "F27" 4 "F17" 5 "F58" ;
VAL_ 1736 rod_id 0 "F1011" 1 "F36" 2 "F46" 3 "F27" 4 "F17" 5 "F58" ;
VAL_ 1744 rod_id 0 "F1011" 1 "F36" 2 "F46" 3 "F27" 4 "F17" 5 "F58" ;
VAL_ 1752 rod_id 0 "F1011" 1 "F36" 2 "F46" 3 "F27" 4 "F17" 5 "F58" ;
VAL_ 1760 device_id 0 "hv_mainboard" 1 "hv_cellboard" 2 "lv" 3 "ecu" 4 "tlm" 5 "traction_control" 6 "steeering_wheel" 7 "handcart" 8 "acquisinator" ;
VAL_ 1768 device_id 0 "hv_mainboard" 1 "hv_cellboard" 2 "lv" 3 "ecu" 4 "tlm" 5 "traction_control" 6 "steeering_wheel" 7 "handcart" 8 "acquisinator" ;
VAL_ 1776 device_id 0 "hv_mainboard" 1 "hv_cellboard" 2 "lv" 3 "ecu" 4 "tlm" 5 "traction_control" 6 "steeering_wheel" 7 "handcart" 8 "acquisinator" ;
VAL_ 1784 device_id 0 "hv_mainboard" 1 "hv_cellboard" 2 "lv" 3 "ecu" 4 "tlm" 5 "traction_control" 6 "steeering_wheel" 7 "handcart" 8 "acquisinator" ;
